# ESP32S31_RADIO register map
Vendor: Espressif; Series: ESP32-S31; File version: 3.52
Registers are 32-bit, read-write, no defined reset value unless marked. A register's access mark holds for its fields unless they carry their own. Offsets are from the block's base; [hi:lo] are bit positions; {n}, {i} and the like mark numbered series.

## WIFI_MAC_TX_COMMON — Shared Wi-Fi CCA, timeout and completion state used by MAC transmit queues and the PHY-owned Wi-Fi CCA gate.
Base 0x20104C5C
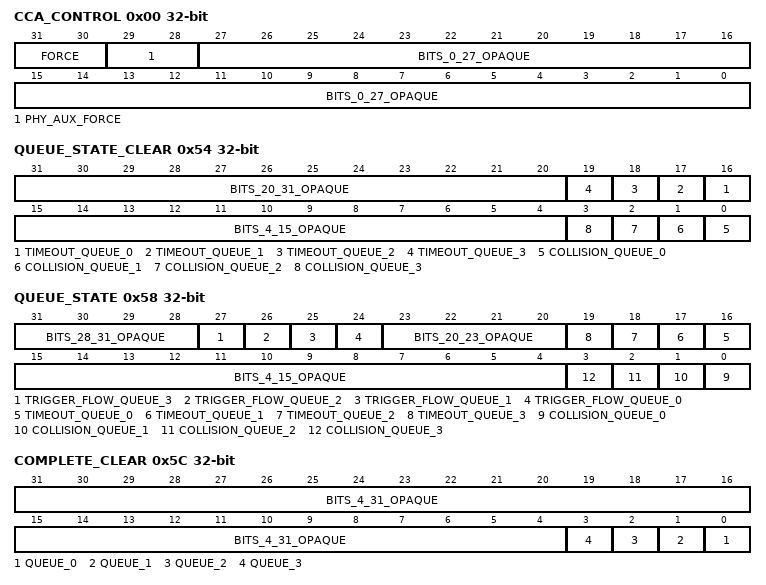
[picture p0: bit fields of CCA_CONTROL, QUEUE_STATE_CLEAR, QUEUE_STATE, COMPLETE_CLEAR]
0x00 CCA_CONTROL — Project-assigned name. Global Wi-Fi TX CCA control; complete PHY enable/disable leaves update the high two fields through separate fresh reads.
  [31:30] FORCE — Project-assigned name. Value three suppresses CCA while invalidating a timed-out queue. Complete phy_disable_cca writes encoding two and complete phy_enable_cca writes zero.
  [29:28] PHY_AUX_FORCE — Project-assigned name. Complete phy_disable_cca writes encoding two and complete phy_enable_cca writes zero in their second fresh-read edge.
  [27:0] BITS_0_27_OPAQUE — Opaque: meaning not established.
0x54 QUEUE_STATE_CLEAR wo write-1-clears — Project-assigned name. Queue collision/timeout state acknowledgement.
  [31:20] BITS_20_31_OPAQUE — Opaque: meaning not established.
  [n+16] TIMEOUT_QUEUE_{n} (n=0..3) — Project-assigned name.
  [15:4] BITS_4_15_OPAQUE — Opaque: meaning not established.
  [n] COLLISION_QUEUE_{n} (n=0..3) — Project-assigned name.
0x58 QUEUE_STATE ro — Project-assigned name. Per-queue timeout and trigger-flow state. The complete trigger-flow HAL getter returns the entire high byte; the complete completion dispatcher then right-shifts it by the completed queue number and tests bit zero.
  [31:28] BITS_28_31_OPAQUE — Opaque: meaning not established. The complete HAL returns four additional high bitmap bits whose bounded ordinary-queue meaning remains unresolved.
  [27] TRIGGER_FLOW_QUEUE_3 — Project-assigned name.
  [26] TRIGGER_FLOW_QUEUE_2 — Project-assigned name.
  [25] TRIGGER_FLOW_QUEUE_1 — Project-assigned name.
  [24] TRIGGER_FLOW_QUEUE_0 — Project-assigned name. Queue zero is participating in the hardware Trigger-based transmit flow.
  [23:20] BITS_20_23_OPAQUE — Opaque: meaning not established.
  [n+16] TIMEOUT_QUEUE_{n} (n=0..3) — Project-assigned name.
  [15:4] BITS_4_15_OPAQUE — Opaque: meaning not established.
  [n] COLLISION_QUEUE_{n} (n=0..3) — Project-assigned name.
0x5C COMPLETE_CLEAR write-1-clears — Project-assigned name. Preserved-image acknowledgement for ordinary queue completion bits.
  [31:4] BITS_4_31_OPAQUE — Opaque: meaning not established.
  [n] QUEUE_{n} (n=0..3) — Project-assigned name.
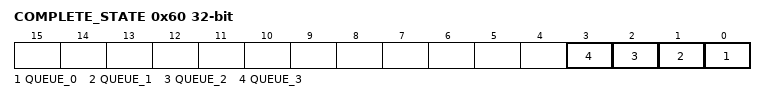
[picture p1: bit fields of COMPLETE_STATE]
0x60 COMPLETE_STATE ro — Project-assigned name. Low four bits report completed ordinary queues 0..3.
  [n] QUEUE_{n} (n=0..3) — Project-assigned name.

## WIFI_MAC_BEAMFORMING_REPORT — Complete esp_test_get_bfr_avgsnr reads the low byte at 0x20105f94 as stream-zero average-SNR code. Code 0x7f is a special saturated/invalid value rendered with a greater-than-or-equal prefix; every other code is converted to dB as (code + 88) / 4.
Base 0x20105F94
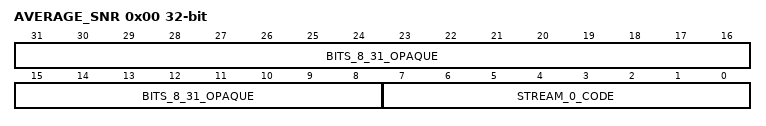
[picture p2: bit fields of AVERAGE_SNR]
0x00 AVERAGE_SNR ro — Project-assigned name. Beamforming-report average SNR observation used by complete esp_test_get_bfr_avgsnr.
  [31:8] BITS_8_31_OPAQUE — Opaque: meaning not established.
  [7:0] STREAM_0_CODE — Project-assigned name. Unsigned raw code. Values other than 0x7f convert to quarter-dB units after adding 88.

## WIFI_MAC_TX_COMPLETION — Non-aliased words from four 0x7c-byte completion banks representing logical EDCA queues 3,2,1,0. AUX_A/AUX_B are canonically described by the richer TX BlockAck high-address and TX queue-information registers in WIFI_MAC_RX_DMA.
Base 0x201053B0
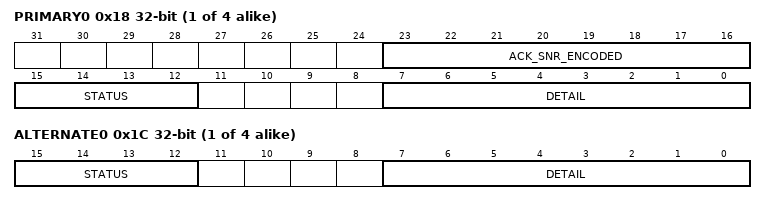
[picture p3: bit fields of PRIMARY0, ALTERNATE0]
{0x18+0x7C*i} PRIMARY{i} (i=0..3) ro — Project-assigned name. Primary completion/status word. Complete libpp[hal_mac_tx.o]::hal_mac_get_txq_complete copies bits 23:16 to result byte two independently of the primary/alternate status selector; complete libpp[lmac.o]::lmacProcessTxSuccess stores that byte as encoded ACK SNR.
  [23:16] ACK_SNR_ENCODED — Project-assigned name. Complete libpp[hal_mac_tx.o]::hal_mac_get_txq_complete copies PRIMARY bits 23:16 to result byte two. Complete libpp[lmac.o]::lmacProcessTxSuccess passes that byte into the descriptor ACK-SNR slot. Complete libpp[trc.o]::rcUpdateTxDone adds the pinned wDevCtrl byte 0x60 and narrows to a signed byte before libpp[trc.o]::rcUpdateAckSnr. This field is meaningful only for a successful completion.
  [15:12] STATUS — Project-assigned name. Four-bit top-level completion status selected by complete libpp[hal_mac_tx.o]::hal_mac_get_txq_complete and dispatched by complete libpp[lmac.o]::lmacProcessTxComplete.
  [7:0] DETAIL — Project-assigned name. Low completion detail byte passed by complete libpp[lmac.o]::lmacProcessTxComplete to the status-one/status-four secondary dispatchers when PRIMARY is selected.
{0x1C+0x7C*i} ALTERNATE{i} (i=0..3) ro — Project-assigned name. Alternate completion/status word selected by the recovered auxiliary bit.
  [15:12] STATUS — Project-assigned name. Four-bit top-level completion status used when the auxiliary selector chooses ALTERNATE.
  [7:0] DETAIL — Project-assigned name. Low completion detail byte used by the status-one/status-four secondary dispatchers when the auxiliary selector chooses ALTERNATE.
{0x28+0x7C*i} AUX_C{i} (i=0..3) ro — Project-assigned name. Third auxiliary completion word contributing to the second decoded extension image.
  [13:7] SECONDARY_TRIGGER_BASED_PACKET_COUNT — Project-assigned name. Complete libpp[hal_mac_tx.o]::hal_mac_get_txq_complete contributes AUX_C bits 13:7 to reconstructed extension word one; complete libpp[lmac.o]::lmacProcessTxComplete shifts that image right by two before storing the seven-bit secondary Trigger-based packet count.
